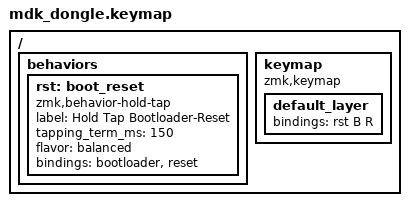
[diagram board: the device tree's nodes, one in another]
/*
 * Copyright (c) 2020 The ZMK Contributors
 *
 * SPDX-License-Identifier: MIT
 */

#include <behaviors.dtsi>
#include <dt-bindings/zmk/keys.h>
#include <dt-bindings/zmk/bt.h>

/ {
	behaviors {
		rst: boot_reset {
			compatible = "zmk,behavior-hold-tap";
			label = "Hold Tap Bootloader-Reset";
			#binding-cells = <2>;
			tapping_term_ms = <150>;
			flavor = "balanced";
			bindings = <&bootloader>, <&reset>;
		};
	};

	keymap {
		compatible = "zmk,keymap";
		
		default_layer {
			bindings = <
				&rst B R
			>;
		};
	};
};
